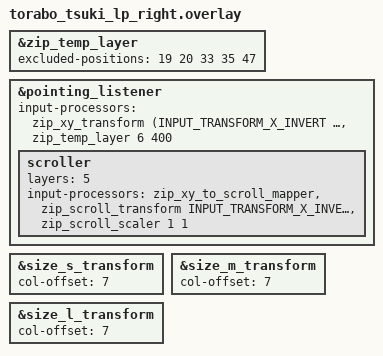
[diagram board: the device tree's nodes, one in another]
#include "torabo_tsuki_lp.dtsi"
#include <input/processors.dtsi>
#include <dt-bindings/zmk/input_transform.h>

// excluded-positions以外のキーを押すとAMLが解除される。positionsは、torabo_tsuki_lp_layout.dtsiのposition_mapと同じ順番で指定する必要がある。
&zip_temp_layer {
    excluded-positions = <
        19 // U
        20 // I
        33 // J
        35 // L
        47 // M
    >;
};

&pointing_listener {
    input-processors = <&zip_xy_transform (INPUT_TRANSFORM_X_INVERT | INPUT_TRANSFORM_Y_INVERT)>,
                       <&zip_temp_layer 6 400>;

    scroller {
        layers = <5>;
        input-processors = 
            <&zip_xy_to_scroll_mapper>,
            <&zip_scroll_transform INPUT_TRANSFORM_X_INVERT>,
            <&zip_scroll_scaler 1 1>;
    };
};

&size_s_transform {
    col-offset = <7>;
};

&size_m_transform {
    col-offset = <7>;
};

&size_l_transform {
    col-offset = <7>;
};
